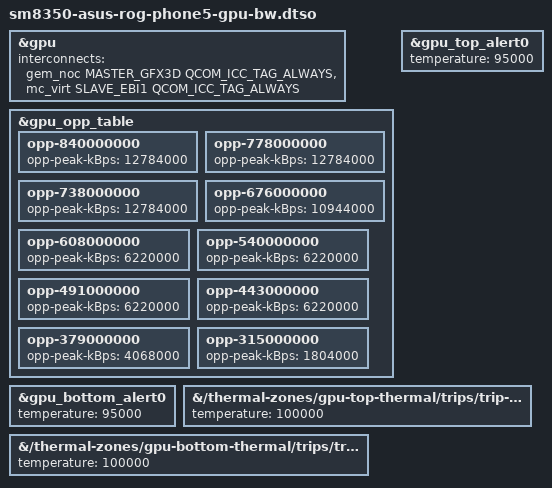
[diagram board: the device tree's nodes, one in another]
// SPDX-License-Identifier: BSD-3-Clause
/*
 * GPU DDR bandwidth votes. The GPU gets its gfx-mem path (GEM NoC to EBI1)
 * and every GPU OPP a peak bandwidth. msm sets the GPU OPP on every frequency
 * change and on resume, and clears it on suspend, so the CPU side votes DDR per
 * GPU frequency through the interconnect framework. (GMU-side voting with the
 * a660 BCM list, former patch 0046, made the GMU miss HFI_H2F_MSG_GX_BW_PERF_VOTE
 * deadlines by over 1 s on r30 and r35, and was dropped.)
 *
 * Values are the stock LPDDR5 (ddr8) nominal bus levels for speed bin 0
 * (lahaina-v2-gpu.dtsi qcom,bus-freq-ddr8 indexing qcom,bus-table-ddr8,
 * MHZ_TO_KBPS(mhz, 4)): 840/778/738 MHz -> 3196 MHz DDR, 676 -> 2736,
 * 608-443 -> 1555, 379 -> 1017, 315 -> 451.
 *
 * GPU junction trips at the stock 95 C (lahaina-thermal.dtsi gpuss zones)
 * instead of sm8350.dtsi's 85 C passive, which throttled the GPU 10 C early;
 * the hot trips move above them.
 */
/dts-v1/;
/plugin/;

#include <dt-bindings/interconnect/qcom,icc.h>
#include <dt-bindings/interconnect/qcom,sm8350.h>

&gpu {
	interconnects = <&gem_noc MASTER_GFX3D QCOM_ICC_TAG_ALWAYS
			 &mc_virt SLAVE_EBI1 QCOM_ICC_TAG_ALWAYS>;
	interconnect-names = "gfx-mem";
};

&gpu_opp_table {
	opp-840000000 {
		opp-peak-kBps = <12784000>;
	};

	opp-778000000 {
		opp-peak-kBps = <12784000>;
	};

	opp-738000000 {
		opp-peak-kBps = <12784000>;
	};

	opp-676000000 {
		opp-peak-kBps = <10944000>;
	};

	opp-608000000 {
		opp-peak-kBps = <6220000>;
	};

	opp-540000000 {
		opp-peak-kBps = <6220000>;
	};

	opp-491000000 {
		opp-peak-kBps = <6220000>;
	};

	opp-443000000 {
		opp-peak-kBps = <6220000>;
	};

	opp-379000000 {
		opp-peak-kBps = <4068000>;
	};

	opp-315000000 {
		opp-peak-kBps = <1804000>;
	};
};

&gpu_top_alert0 {
	temperature = <95000>;
};

&gpu_bottom_alert0 {
	temperature = <95000>;
};

&{/thermal-zones/gpu-top-thermal/trips/trip-point1} {
	temperature = <100000>;
};

&{/thermal-zones/gpu-bottom-thermal/trips/trip-point1} {
	temperature = <100000>;
};
